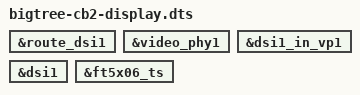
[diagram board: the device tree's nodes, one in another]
/dts-v1/;
/plugin/;

/ {

	fragment@0 {
		target = <&route_dsi1>;

		__overlay__ {
			status = "okay";
		};
	};

	fragment@1 {
		target = <&video_phy1>;

		__overlay__ {
			 status = "okay";
		};
	};

	fragment@2 {
		target = <&dsi1_in_vp1>;

		__overlay__ {
			status = "okay";
		};
	};

	fragment@3 {
		target = <&dsi1>;

		__overlay__ {
			status = "okay";
		};
	};
	
	fragment@4 {
		target = <&ft5x06_ts>;

		__overlay__ {
			 status = "okay";
		};
	};
	
};
